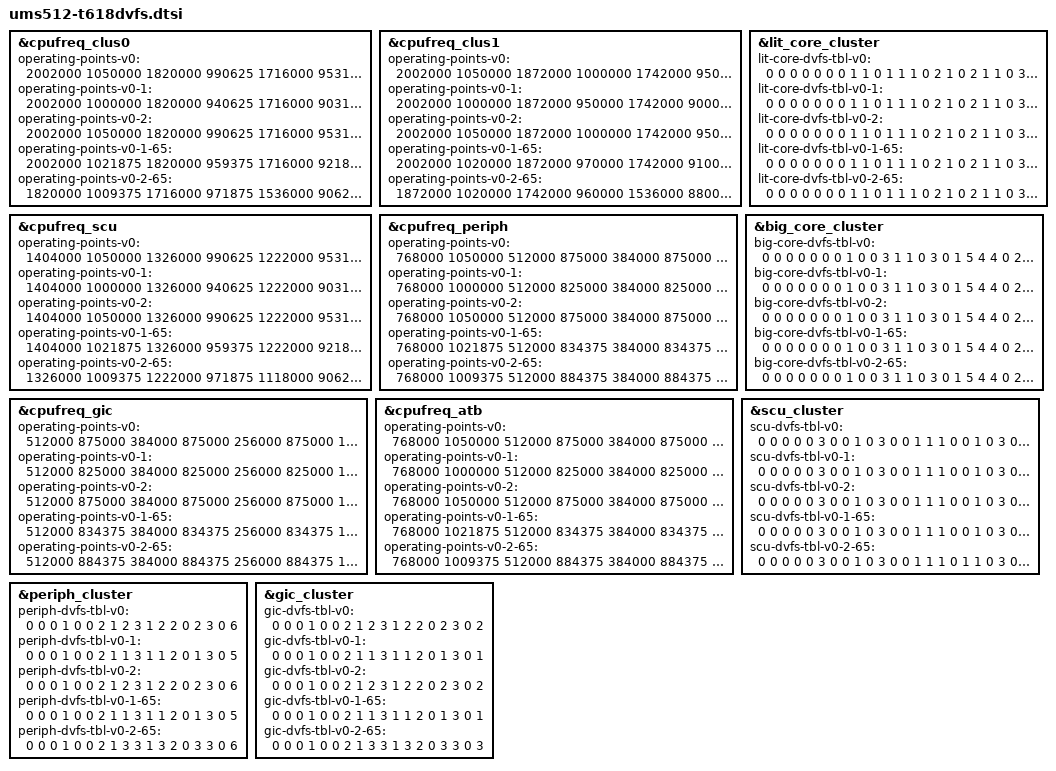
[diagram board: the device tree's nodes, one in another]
// SPDX-License-Identifier: (GPL-2.0+ OR MIT)
/*
 * Unisoc Sharkl5Pro platform T610 SOC DVFS DTS file
 *
 * Copyright (C) 2019, Unisoc Communications Inc.
 */

#include "sharkl5Pro.dtsi"
#include "ums512.dtsi"

&cpufreq_clus0 {
	/* operating-points-v0-0-0
	 * v0/v0-soc_ver 0-binning 0-temp
	 * v0-T618 v1-T610
	 */
	operating-points-v0 = <
		/* kHZ   uV */
		2002000 1050000
		1820000 990625
		1716000 953125
		1536000 890625
		1482000 875000
		1228800 787500
		1144000 756250
		962000  756250
		768000  756250
		614400  756250
	>;

	operating-points-v0-1 = <
		/* kHZ   uV */
		2002000 1000000
		1820000 940625
		1716000 903125
		1536000 840625
		1482000 825000
		1228800 750000
		1144000 750000
		962000  750000
		768000  750000
		614400  750000
	>;

	operating-points-v0-2 = <
		/* kHZ   uV */
		2002000 1050000
		1820000 990625
		1716000 953125
		1536000 890625
		1482000 875000
		1228800 787500
		1144000 756250
		962000  756250
		768000  756250
		614400  756250
	>;

	operating-points-v0-1-65 = <
		/* kHZ   uV */
		2002000 1021875
		1820000 959375
		1716000 921875
		1536000 853125
		1482000 834375
		1228800 750000
		1144000 750000
		962000  750000
		768000  750000
		614400  750000
	>;

	operating-points-v0-2-65 = <
		/* kHZ   uV */
		1820000 1009375
		1716000 971875
		1536000 906250
		1482000 884375
		1228800 793750
		1144000 762500
		962000  750000
		768000  750000
		614400  750000
	>;
};

&cpufreq_clus1 {
	operating-points-v0 = <
		/* kHZ   uV */
		2002000 1050000
		1872000 1000000
		1742000 950000
		1536000	870000
		1482000	850000
		1228800	750000
	>;

	operating-points-v0-1 = <
		/* kHZ   uV */
		2002000 1000000
		1872000 950000
		1742000 900000
		1536000	820000
		1482000	800000
		1228800	750000
	>;

	operating-points-v0-2 = <
		/* kHZ   uV */
		2002000 1050000
		1872000 1000000
		1742000 950000
		1536000	870000
		1482000	850000
		1228800	750000
	>;

	operating-points-v0-1-65 = <
		/* kHZ   uV */
		2002000 1020000
		1872000 970000
		1742000 910000
		1536000	820000
		1482000	800000
		1228800	750000
	>;

	operating-points-v0-2-65 = <
		/* kHZ   uV */
		1872000 1020000
		1742000 960000
		1536000	880000
		1482000	850000
		1228800	750000
	>;
};

&cpufreq_scu {
	operating-points-v0 = <
		/* kHz   uV */
		1404000 1050000
		1326000 990625
		1222000 953125
		1118000 890625
		1014000 875000
		962000  787500
		768000  756250
		650000  756250
		546000  756250
	>;

	operating-points-v0-1 = <
		/* kHz   uV */
		1404000 1000000
		1326000 940625
		1222000 903125
		1118000 840625
		1014000 825000
		962000  750000
		768000  750000
		650000  750000
		546000  750000
	>;

	operating-points-v0-2 = <
		/* kHz   uV */
		1404000 1050000
		1326000 990625
		1222000 953125
		1118000 890625
		1014000 875000
		962000  787500
		768000  756250
		650000  756250
		546000  756250
	>;

	operating-points-v0-1-65 = <
		/* kHz   uV */
		1404000 1021875
		1326000 959375
		1222000 921875
		1118000 853125
		1014000 834375
		962000  750000
		768000  750000
		650000  750000
		546000  750000
	>;

	operating-points-v0-2-65 = <
		/* kHz   uV */
		1326000 1009375
		1222000 971875
		1118000 906250
		1014000 884375
		962000  793750
		768000  762500
		650000  750000
		546000  750000
	>;
};

&cpufreq_periph {
	operating-points-v0 = <
		/* kHZ  uV */
		768000 1050000
		512000 875000
		384000 875000
		256000 875000
		153600 756250
	>;

	operating-points-v0-1 = <
		/* kHZ  uV */
		768000 1000000
		512000 825000
		384000 825000
		256000 825000
		153600 750000
	>;

	operating-points-v0-2 = <
		/* kHZ  uV */
		768000 1050000
		512000 875000
		384000 875000
		256000 875000
		153600 756250
	>;

	operating-points-v0-1-65 = <
		/* kHZ  uV */
		768000 1021875
		512000 834375
		384000 834375
		256000 834375
		153600 750000
	>;

	operating-points-v0-2-65 = <
		/* kHZ  uV */
		768000 1009375
		512000 884375
		384000 884375
		256000 884375
		153600 757000
	>;

};

&cpufreq_gic {
	operating-points-v0 = <
		/* kHZ  uV */
		512000 875000
		384000 875000
		256000 875000
		192000 875000
		153600 756250
	>;

	operating-points-v0-1 = <
		/* kHZ  uV */
		512000 825000
		384000 825000
		256000 825000
		192000 825000
		153600 750000
	>;

	operating-points-v0-2 = <
		/* kHZ  uV */
		512000 875000
		384000 875000
		256000 875000
		192000 875000
		153600 756250
	>;

	operating-points-v0-1-65 = <
		/* kHZ  uV */
		512000 834375
		384000 834375
		256000 834375
		192000 834375
		153600 750000
	>;

	operating-points-v0-2-65 = <
		/* kHZ  uV */
		512000 884375
		384000 884375
		256000 884375
		192000 884375
		153600 750000
	>;
};

&cpufreq_atb {
	operating-points-v0 = <
		/* kHZ  uV */
		768000 1050000
		512000 875000
		384000 875000
		256000 756250
		153600 756250
	>;

	operating-points-v0-1 = <
		/* kHZ  uV */
		768000 1000000
		512000 825000
		384000 825000
		256000 750000
		153600 750000
	>;

	operating-points-v0-2 = <
		/* kHZ  uV */
		768000 1050000
		512000 875000
		384000 875000
		256000 756250
		153600 756250
	>;

	operating-points-v0-1-65 = <
		/* kHZ  uV */
		768000 1021875
		512000 834375
		384000 834375
		256000 750000
		153600 750000
	>;

	operating-points-v0-2-65 = <
		/* kHZ  uV */
		768000 1009375
		512000 884375
		384000 884375
		256000 750000
		153600 750000
	>;
};

&lit_core_cluster{
	/* lit-core-dvfs-tbl-v0-0-0
	 * v0/v1-soc_ver v0-T618 v1-T610 0-binning 0-temp
	 * sel, div, vol, vote_scu, vote_peri, vote_gic, mpllx
	 */
	lit-core-dvfs-tbl-v0 = <
		0 0 0 0 0 0 0
		1 1 0 1 1 1 0
		2 1 0 2 1 1 0
		3 0 0 2 1 1 0
		3 0 0 3 1 1 1
		1 0 1 4 1 1 0
		3 0 2 5 4 4 2
		2 0 3 6 4 4 0
		3 0 4 7 4 5 3
		3 0 5 8 4 5 4
		3 0 6 9 5 5 5
	>;

	lit-core-dvfs-tbl-v0-1 = <
		0 0 0 0 0 0 0
		1 1 0 1 1 1 0
		2 1 0 2 1 1 0
		3 0 0 2 1 1 0
		3 0 0 3 1 1 1
		1 0 0 4 1 1 0
		3 0 1 5 4 4 2
		2 0 2 6 4 4 0
		3 0 3 7 4 5 3
		3 0 4 8 4 5 4
		3 0 5 9 5 5 5
	>;

	lit-core-dvfs-tbl-v0-2 = <
		0 0 0 0 0 0 0
		1 1 0 1 1 1 0
		2 1 0 2 1 1 0
		3 0 0 2 1 1 0
		3 0 0 3 1 1 1
		1 0 1 4 1 1 0
		3 0 2 5 4 4 2
		2 0 3 6 4 4 0
		3 0 4 7 4 5 3
		3 0 5 8 4 5 4
		3 0 6 9 5 5 5
	>;

	lit-core-dvfs-tbl-v0-1-65 = <
		0 0 0 0 0 0 0
		1 1 0 1 1 1 0
		2 1 0 2 1 1 0
		3 0 0 2 1 1 0
		3 0 0 3 1 1 1
		1 0 0 4 1 1 0
		3 0 1 5 4 4 2
		2 0 2 6 4 4 0
		3 0 3 7 4 5 3
		3 0 4 8 4 5 4
		3 0 5 9 5 5 5
	>;

	lit-core-dvfs-tbl-v0-2-65 = <
		0 0 0 0 0 0 0
		1 1 0 1 1 1 0
		2 1 0 2 1 1 0
		3 0 0 2 1 1 0
		3 0 1 3 1 1 1
		1 0 2 4 1 1 0
		3 0 3 5 4 4 2
		2 0 4 6 4 4 0
		3 0 5 7 4 5 3
		3 0 6 8 4 5 4
		3 0 6 8 4 5 4
	>;
};

&big_core_cluster {
	/* sel, div, vol, vote_scu, vote_peri, vote_gic, mpllx */
	big-core-dvfs-tbl-v0 = <
		0 0 0 0 0 0 0
		1 0 0 3 1 1 0
		3 0 1 5 4 4 0
		2 0 2 6 4 4 0
		3 0 3 7 4 5 1
		3 0 4 8 4 5 3
		3 0 5 9 5 5 4
	>;

	big-core-dvfs-tbl-v0-1 = <
		0 0 0 0 0 0 0
		1 0 0 3 1 1 0
		3 0 1 5 4 4 0
		2 0 2 6 4 4 0
		3 0 3 7 4 5 1
		3 0 4 8 4 5 3
		3 0 5 9 5 5 4
	>;

	big-core-dvfs-tbl-v0-2 = <
		0 0 0 0 0 0 0
		1 0 0 3 1 1 0
		3 0 1 5 4 4 0
		2 0 2 6 4 4 0
		3 0 3 7 4 5 1
		3 0 4 8 4 5 3
		3 0 5 9 5 5 4
	>;

	big-core-dvfs-tbl-v0-1-65 = <
		0 0 0 0 0 0 0
		1 0 0 3 1 1 0
		3 0 1 5 4 4 0
		2 0 2 6 4 4 0
		3 0 3 7 4 5 1
		3 0 4 8 4 5 3
		3 0 5 9 5 5 4
	>;

	big-core-dvfs-tbl-v0-2-65 = <
		0 0 0 0 0 0 0
		1 0 0 3 1 1 0
		3 0 1 5 4 4 0
		2 0 2 6 4 4 0
		3 0 3 7 4 5 1
		3 0 4 8 4 5 3
		3 0 4 8 4 5 3
	>;
};

&scu_cluster {
	/* sel div vol ace_div mpllx */
	scu-dvfs-tbl-v0 = <
		0 0 0 0 0
		3 0 0 1 0
		3 0 0 1 1
		1 0 0 1 0
		3 0 1 1 2
		3 0 2 1 3
		3 0 3 1 4
		3 0 4 1 5
		3 0 5 1 6
		3 0 6 1 7
	>;

	scu-dvfs-tbl-v0-1 = <
		0 0 0 0 0
		3 0 0 1 0
		3 0 0 1 1
		1 0 0 1 0
		3 0 0 1 2
		3 0 1 1 3
		3 0 2 1 4
		3 0 3 1 5
		3 0 4 1 6
		3 0 5 1 7
	>;

	scu-dvfs-tbl-v0-2 = <
		0 0 0 0 0
		3 0 0 1 0
		3 0 0 1 1
		1 0 0 1 0
		3 0 1 1 2
		3 0 2 1 3
		3 0 3 1 4
		3 0 4 1 5
		3 0 5 1 6
		3 0 6 1 7
	>;

	scu-dvfs-tbl-v0-1-65 = <
		0 0 0 0 0
		3 0 0 1 0
		3 0 0 1 1
		1 0 0 1 0
		3 0 0 1 2
		3 0 1 1 3
		3 0 2 1 4
		3 0 3 1 5
		3 0 4 1 6
		3 0 5 1 7
	>;

	scu-dvfs-tbl-v0-2-65 = <
		0 0 0 0 0
		3 0 0 1 0
		3 0 0 1 1
		1 0 1 1 0
		3 0 2 1 2
		3 0 3 1 3
		3 0 4 1 4
		3 0 5 1 5
		3 0 6 1 6
		3 0 6 1 6
	>;
};

&periph_cluster{
	/* sel div vol */
	periph-dvfs-tbl-v0 = <
		0 0 0
		1 0 0
		2 1 2
		3 1 2
		2 0 2
		3 0 6
	>;

	periph-dvfs-tbl-v0-1 = <
		0 0 0
		1 0 0
		2 1 1
		3 1 1
		2 0 1
		3 0 5
	>;

	periph-dvfs-tbl-v0-2 = <
		0 0 0
		1 0 0
		2 1 2
		3 1 2
		2 0 2
		3 0 6
	>;

	periph-dvfs-tbl-v0-1-65 = <
		0 0 0
		1 0 0
		2 1 1
		3 1 1
		2 0 1
		3 0 5
	>;

	periph-dvfs-tbl-v0-2-65 = <
		0 0 0
		1 0 0
		2 1 3
		3 1 3
		2 0 3
		3 0 6
	>;
};

&gic_cluster {
	/*sel div vol*/
	gic-dvfs-tbl-v0 = <
		0 0 0
		1 0 0
		2 1 2
		3 1 2
		2 0 2
		3 0 2
	>;

	gic-dvfs-tbl-v0-1 = <
		0 0 0
		1 0 0
		2 1 1
		3 1 1
		2 0 1
		3 0 1
	>;

	gic-dvfs-tbl-v0-2 = <
		0 0 0
		1 0 0
		2 1 2
		3 1 2
		2 0 2
		3 0 2
	>;

	gic-dvfs-tbl-v0-1-65 = <
		0 0 0
		1 0 0
		2 1 1
		3 1 1
		2 0 1
		3 0 1
	>;

	gic-dvfs-tbl-v0-2-65 = <
		0 0 0
		1 0 0
		2 1 3
		3 1 3
		2 0 3
		3 0 3
	>;
};
